# ipro7 register map
Vendor: intelpro; Series: BTBLE
CPU: ipro7, little endian
Registers are 32-bit, read-write, reset 0x0 unless marked. A register's access mark holds for its fields unless they carry their own. Offsets are from the block's base; [hi:lo] are bit positions.

## TSRC
Base 0x3004D000
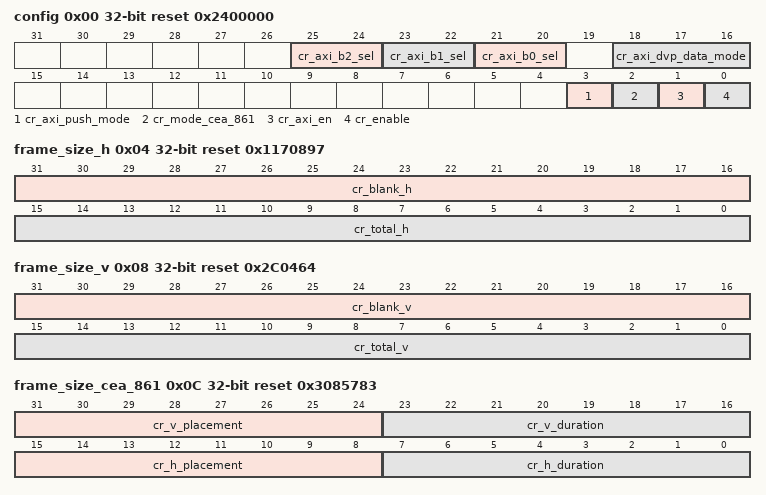
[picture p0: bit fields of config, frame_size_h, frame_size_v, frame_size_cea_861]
0x00 config reset 0x2400000
  [25:24] cr_axi_b2_sel — AXI2DVP Byte2 Selection
  [23:22] cr_axi_b1_sel — AXI2DVP Byte1 Selection
  [21:20] cr_axi_b0_sel — AXI2DVP Byte0 Selection
  [18:16] cr_axi_dvp_data_mode — AXI2DVP pixel data mode 3'd0 : 16bit mode (YUV422 INTV) 3'd1 : 24bit mode(RGB888) 3'd2 : 16bit extend 24bit (RGB565) 3'd3 : 32bit compress 24bit (RGBA8888) 3'd4 : 8bit mode (YUV400) 3'd5 : 12bit mode
  [3] cr_axi_push_mode — Enable AXI fetch memoy push mode Effect only when cr_axi_en==1 && cr_axi_swap_mode==0
  [2] cr_mode_cea_861 — Mode select 1'b1: EIA/CEA-861 mode 1'b0: Sensor DVP mode
  [1] cr_axi_en — Enable signal of axi2dvp function (don't care if cr_snsr_en is enabled) 1'b1: pix_data is from AXI 1'b0: pix_data is fake gradient data
  [0] cr_enable — Enable signal
0x04 frame_size_h reset 0x1170897
  [31:16] cr_blank_h — Horizontal blank stage pixel count
  [15:0] cr_total_h — Horizontal total pixel count
0x08 frame_size_v reset 0x2C0464
  [31:16] cr_blank_v — Vertical blank stage pixel count
  [15:0] cr_total_v — Vertical total pixel count
0x0C frame_size_cea_861 reset 0x3085783
  [31:24] cr_v_placement — VSYNC start position, relative to blank start position (for CEA-861 mode only)
  [23:16] cr_v_duration — VSYNC end position, relative to blank start position (for CEA-861 mode only)
  [15:8] cr_h_placement — HSYNC start position, relative to blank start position (for CEA-861 mode only)
  [7:0] cr_h_duration — HSYNC end position, relative to blank start position (for CEA-861 mode only)
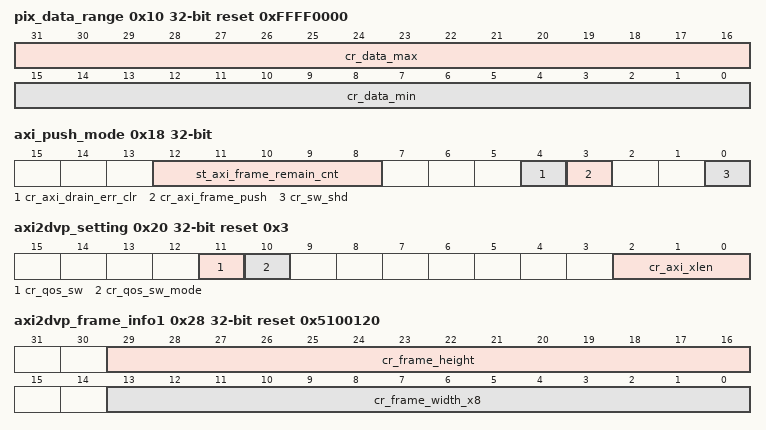
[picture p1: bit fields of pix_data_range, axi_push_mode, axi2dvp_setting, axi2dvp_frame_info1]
0x10 pix_data_range reset 0xFFFF0000
  [31:16] cr_data_max — Maximum data value of fake gradient data (don't care if pix_data is not the fake gradient)
  [15:0] cr_data_min — Mininum data value of fake gradient data (don't care if pix_data is not the fake gradient)
0x14 pix_data_step reset 0x1
  [7:0] cr_data_step — Data step value for each line of fake gradient data (don't care if pix_data is not the fake gradient)
0x18 axi_push_mode (reset mask 0xFFFFE0FF)
  [12:8] st_axi_frame_remain_cnt ro — Frame remain count for axi frame push mode
  [4] cr_axi_drain_err_clr wo — axi2dvp drain_error clear signal
  [3] cr_axi_frame_push wo — Frame push for axi frame push mode
  [0] cr_sw_shd wo — Soft force shadow (Must set once before enable)
0x20 axi2dvp_setting reset 0x3
  [11] cr_qos_sw — AXI Qos software mode value
  [10] cr_qos_sw_mode — AXI QoS software mode enable
  [2:0] cr_axi_xlen — burst length setting 3'd0 - Single / 3'd1 - INCR4 / 3'd2 - INCR8 3'd3 - INCR16 / 3'd5 - INCR32 / 3'd6 - INCR64
0x24 axi2dvp_start_addr_by
  [31:0] cr_axi_start_addr_by — axi2dvp start address for Bayer or Y-planar (also frame 0 of swap mode)
0x28 axi2dvp_frame_info1 reset 0x5100120
  [29:16] cr_frame_height — Frame hight (unit - line)
  [13:0] cr_frame_width_x8 — Frame real write width / 8 (unit - byte)
0x30 axi2dvp_swap_addr_by
  [31:0] cr_axi_swap_addr_by — axi2dvp swap address for Bayer or Y-planar
0x34 axi2dvp_prefetch reset 0x28
  [15:0] cr_prefetch_v — Vertical prefetch start position, relative to blank start position (should be less than cr_blank_v)_x000D_ (don't care if pix_data is not from AXI)
0x38 axi2dvp_frame_info2
  [13:0] cr_stride_width_x8 — Frame stride width / 8 (unit - byte)
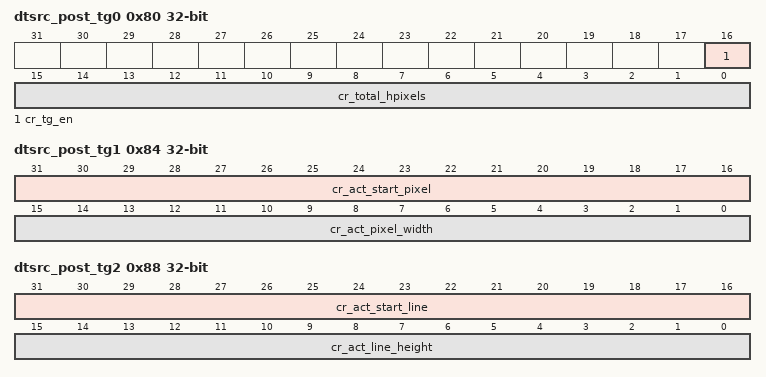
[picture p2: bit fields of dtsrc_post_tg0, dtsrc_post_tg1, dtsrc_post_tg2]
0x80 dtsrc_post_tg0
  [16] cr_tg_en — Auto generate hsync enable
  [15:0] cr_total_hpixels — Auto generate hsync - Total h-pixels
0x84 dtsrc_post_tg1
  [31:16] cr_act_start_pixel — Auto generate hsync - Start active pixel
  [15:0] cr_act_pixel_width — Auto generate hsync - Frame pixel-width
0x88 dtsrc_post_tg2
  [31:16] cr_act_start_line — Auto generate hsync - Start active line
  [15:0] cr_act_line_height — Auto generate hsync - Frame line-height
